VERSION "1.0"

NS_ :

BS_:

BU_: PCU SAS
VAL_TABLE_ SensorTrimmed 1 "Sensor trimmed" 0 "Sensor not trimmed" ;
VAL_TABLE_ Calibrated 1 "Calibrated" 0 "Not Calibrated" ;
VAL_TABLE_ Valid_notValid 1 "Valid" 0 "NotValid" ;

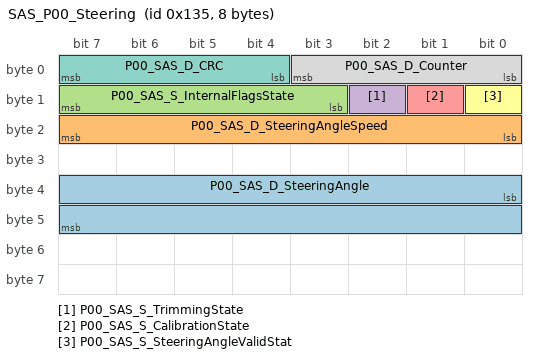
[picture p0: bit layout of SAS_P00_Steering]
BO_ 309 SAS_P00_Steering: 8 SAS
 SG_ P00_SAS_D_SteeringAngle : 32|16@1+ (0.1,-780) [-780|779.9] "deg"  PCU
 SG_ P00_SAS_D_SteeringAngleSpeed : 16|8@1+ (4,0) [0|1016] "deg/sec"  PCU
 SG_ P00_SAS_S_InternalFlagsState : 11|5@1+ (1,0) [0|31] ""  PCU
 SG_ P00_SAS_S_TrimmingState : 10|1@1+ (1,0) [0|1] ""  PCU
 SG_ P00_SAS_S_CalibrationState : 9|1@1+ (1,0) [0|1] ""  PCU
 SG_ P00_SAS_S_SteeringAngleValidStat : 8|1@1+ (1,0) [0|1] ""  PCU
 SG_ P00_SAS_D_CRC : 4|4@1+ (1,0) [0|15] ""  PCU
 SG_ P00_SAS_D_Counter : 0|4@1+ (1,0) [0|15] ""  PCU

CM_ SG_ 309 P00_SAS_D_SteeringAngle "Steering wheel angle ";
CM_ SG_ 309 P00_SAS_D_SteeringAngleSpeed "Steering wheel rotation speed ";
CM_ SG_ 309 P00_SAS_S_InternalFlagsState "Internal flags state (don't use)";
CM_ SG_ 309 P00_SAS_S_TrimmingState "Steering angle sensor trimming State";
CM_ SG_ 309 P00_SAS_S_CalibrationState "Steering angle sensor calibration state";
CM_ SG_ 309 P00_SAS_S_SteeringAngleValidStat "Steering angle sensor validation state";
CM_ SG_ 309 P00_SAS_D_CRC "8 bit CRC";
CM_ SG_ 309 P00_SAS_D_Counter "8 bit up counter";
BA_DEF_ BO_  "TXRX" ENUM  "TX","RX";
BA_DEF_ BO_  "J1939PgAppearanceOnBus" ENUM  "Default","CAN_Extended","CANFD_Extended";
BA_DEF_ SG_  "SigType" ENUM  "Default","Range","RangeSigned","ASCII","Discrete","Control","ReferencePGN","DTC","StringDelimiter","StringLength","StringLengthControl";
BA_DEF_ SG_  "GenSigEVName" STRING ;
BA_DEF_ SG_  "GenSigILSupport" ENUM  "No","Yes";
BA_DEF_ SG_  "GenSigSendType" ENUM  "Cyclic","OnWrite","OnWriteWithRepetition","OnChange","OnChangeWithRepetition","IfActive","IfActiveWithRepetition","NoSigSendType";
BA_DEF_ SG_  "GenSigStartValue" INT 0 2147483647;
BA_DEF_ BO_  "GenMsgILSupport" ENUM  "No","Yes";
BA_DEF_ BU_  "NmStationAddress" INT 0 255;
BA_DEF_ BO_  "GenMsgSendType" ENUM  "cyclic","NotUsed","IfActive","NotUsed","NotUsed","NotUsed","NotUsed","NotUsed","noMsgSendType";
BA_DEF_ BO_  "GenMsgRequestable" INT 0 1;
BA_DEF_ BO_  "GenMsgCycleTime" INT 0 3600000;
BA_DEF_ SG_  "SPN" INT 0 524287;
BA_DEF_  "DBName" STRING ;
BA_DEF_  "BusType" STRING ;
BA_DEF_  "ProtocolType" STRING ;
BA_DEF_ BO_  "VFrameFormat" ENUM  "StandardCAN","ExtendedCAN","reserved","J1939PG","reserved","reserved","reserved","reserved","reserved","reserved","reserved","reserved","reserved","reserved","StandardCAN_FD","ExtendedCAN_FD";
BA_DEF_ SG_  "SystemSignalLongSymbol" STRING ;
BA_DEF_DEF_  "TXRX" "TX";
BA_DEF_DEF_  "J1939PgAppearanceOnBus" "Default";
BA_DEF_DEF_  "SigType" "Default";
BA_DEF_DEF_  "GenSigEVName" "Env@Nodename_@Signame";
BA_DEF_DEF_  "GenSigILSupport" "Yes";
BA_DEF_DEF_  "GenSigSendType" "NoSigSendType";
BA_DEF_DEF_  "GenSigStartValue" 0;
BA_DEF_DEF_  "GenMsgILSupport" "Yes";
BA_DEF_DEF_  "NmStationAddress" 254;
BA_DEF_DEF_  "GenMsgSendType" "noMsgSendType";
BA_DEF_DEF_  "GenMsgRequestable" 1;
BA_DEF_DEF_  "GenMsgCycleTime" 0;
BA_DEF_DEF_  "SPN" 0;
BA_DEF_DEF_  "DBName" "";
BA_DEF_DEF_  "BusType" "CAN";
BA_DEF_DEF_  "ProtocolType" "J1939";
BA_DEF_DEF_  "VFrameFormat" "J1939PG";
BA_DEF_DEF_  "SystemSignalLongSymbol" "";
BA_ "ProtocolType" "CAN";
BA_ "DBName" "SAS";
BA_ "NmStationAddress" BU_ PCU 1;
BA_ "NmStationAddress" BU_ SAS 2;
BA_ "GenMsgCycleTime" BO_ 309 10;
BA_ "VFrameFormat" BO_ 309 0;
BA_ "GenMsgSendType" BO_ 309 0;
BA_ "GenSigStartValue" SG_ 309 P00_SAS_D_SteeringAngle 7800;
BA_ "SPN" SG_ 309 P00_SAS_D_SteeringAngle 445;
BA_ "GenSigSendType" SG_ 309 P00_SAS_D_SteeringAngle 0;
BA_ "SPN" SG_ 309 P00_SAS_D_SteeringAngleSpeed 444;
BA_ "GenSigSendType" SG_ 309 P00_SAS_D_SteeringAngleSpeed 0;
BA_ "SPN" SG_ 309 P00_SAS_S_InternalFlagsState 443;
BA_ "GenSigSendType" SG_ 309 P00_SAS_S_InternalFlagsState 0;
BA_ "SPN" SG_ 309 P00_SAS_S_TrimmingState 442;
BA_ "GenSigSendType" SG_ 309 P00_SAS_S_TrimmingState 0;
BA_ "SPN" SG_ 309 P00_SAS_S_CalibrationState 441;
BA_ "GenSigSendType" SG_ 309 P00_SAS_S_CalibrationState 0;
BA_ "SPN" SG_ 309 P00_SAS_S_SteeringAngleValidStat 440;
BA_ "GenSigSendType" SG_ 309 P00_SAS_S_SteeringAngleValidStat 0;
BA_ "SystemSignalLongSymbol" SG_ 309 P00_SAS_S_SteeringAngleValidStat "P00_SAS_S_SteeringAngleValidState";
BA_ "GenSigSendType" SG_ 309 P00_SAS_D_CRC 0;
BA_ "GenSigSendType" SG_ 309 P00_SAS_D_Counter 0;
VAL_ 309 P00_SAS_S_TrimmingState 1 "Trimmed" 0 "Not trimmed" ;
VAL_ 309 P00_SAS_S_CalibrationState 1 "Calibrated" 0 "Not calibrated" ;
VAL_ 309 P00_SAS_S_SteeringAngleValidStat 1 "Valid" 0 "Invalid" ;
